        VERSION ""

        BU_: CH DIPF DIPR ETH FC HVI HVS PARTY SDCV VEH VIRT
        BO_ 962 VCLEFT_switchStatus: 8 VEH
 SG_ VCLEFT_frontBuckleSwitch m0: 48|2@1+ (1,0) [0|3] "" gtw
 SG_ VCLEFT_btnWindowSwPackUpLF m0: 32|1@1+ (1,0) [0|1] "" gtw
 SG_ VCLEFT_frontSeatTrackBack m0: 8|2@1+ (1,0) [0|3] "" gtw
 SG_ VCLEFT_btnWindowSwPackAutoDownLF m0: 35|1@1+ (1,0) [0|1] "" gtw
 SG_ VCLEFT_btnWindowSwPackDownRR m0: 46|1@1+ (1,0) [0|1] "" gtw
 SG_ VCLEFT_btnWindowSwPackAutoUpRR m0: 45|1@1+ (1,0) [0|1] "" gtw
 SG_ VCLEFT_btnWindowSwPackAutoDownRR m0: 47|1@1+ (1,0) [0|1] "" gtw
 SG_ VCLEFT_rightMirrorTilt m0: 5|3@1+ (1,0) [0|4] "" vcright
 SG_ VCLEFT_btnWindowSwPackUpRR m0: 44|1@1+ (1,0) [0|1] "" gtw
 SG_ VCLEFT_frontOccupancySwitch m0: 50|2@1+ (1,0) [0|3] "" gtw
 SG_ VCLEFT_swcRightTiltLeft m1: 8|2@1+ (1,0) [0|3] "" das
 SG_ VCLEFT_rearRightOccupancySwitch m0: 58|2@1+ (1,0) [0|3] "" gtw
 SG_ VCLEFT_btnWindowSwPackDownLF m0: 34|1@1+ (1,0) [0|1] "" gtw
 SG_ VCLEFT_btnWindowSwPackAutoUpLF m0: 33|1@1+ (1,0) [0|1] "" gtw
 SG_ VCLEFT_swcLeftTiltRight m1: 3|2@1+ (1,0) [0|3] "" das
 SG_ VCLEFT_frontSeatBackrestForward m0: 22|2@1+ (1,0) [0|3] "" gtw
 SG_ VCLEFT_swcRightTiltRight m1: 10|2@1+ (1,0) [0|3] "" das
 SG_ VCLEFT_swcLeftScrollTicks m1: 16|6@1- (1,0) [-32|31] "" das
 SG_ VCLEFT_btnWindowUpLR m1: 32|1@1+ (1,0) [0|1] "" gtw
 SG_ VCLEFT_btnWindowAutoDownLR m1: 35|1@1+ (1,0) [0|1] "" gtw
 SG_ VCLEFT_btnWindowSwPackDownRF m0: 42|1@1+ (1,0) [0|1] "" gtw
 SG_ VCLEFT_btnWindowSwPackAutoUpRF m0: 41|1@1+ (1,0) [0|1] "" gtw
 SG_ VCLEFT_frontSeatLumbarIn m0: 28|2@1+ (1,0) [0|3] "" gtw
 SG_ VCLEFT_frontSeatLiftUp m0: 18|2@1+ (1,0) [0|3] "" gtw
 SG_ VCLEFT_btnWindowSwPackDownLR m0: 38|1@1+ (1,0) [0|1] "" gtw
 SG_ VCLEFT_btnWindowSwPackAutoUpLR m0: 37|1@1+ (1,0) [0|1] "" gtw
 SG_ VCLEFT_frontSeatLumbarDown m0: 24|2@1+ (1,0) [0|3] "" gtw
 SG_ VCLEFT_driverPresent m0: 4|1@1+ (1,0) [0|1] "" das
 SG_ VCLEFT_frontSeatTiltDown m0: 12|2@1+ (1,0) [0|3] "" gtw
 SG_ VCLEFT_frontSeatTrackForward m0: 10|2@1+ (1,0) [0|3] "" gtw
 SG_ VCLEFT_rearLeftBuckleSwitch m0: 52|2@1+ (1,0) [0|3] "" gtw
 SG_ VCLEFT_hazardButtonPressed m0: 3|1@1+ (1,0) [0|1] "" gtw
 SG_ VCLEFT_swcRightScrollTicks m1: 24|6@1- (1,0) [-32|31] "" das
 SG_ VCLEFT_swcRightPressed m1: 12|2@1+ (1,0) [0|3] "" das
 SG_ VCLEFT_frontSeatLumbarOut m0: 30|2@1+ (1,0) [0|3] "" gtw
 SG_ VCLEFT_brakePressed m0: 60|1@1+ (1,0) [0|1] "" di
 SG_ VCLEFT_swcLeftTiltLeft m1: 14|2@1+ (1,0) [0|3] "" das
 SG_ VCLEFT_swcLeftPressed m1: 5|2@1+ (1,0) [0|3] "" das
 SG_ VCLEFT_btnWindowSwPackUpLR m0: 36|1@1+ (1,0) [0|1] "" gtw
 SG_ VCLEFT_frontSeatTiltUp m0: 14|2@1+ (1,0) [0|3] "" gtw
 SG_ VCLEFT_rearLeftOccupancySwitch m0: 56|2@1+ (1,0) [0|3] "" gtw
 SG_ VCLEFT_frontSeatBackrestBack m0: 20|2@1+ (1,0) [0|3] "" gtw
 SG_ VCLEFT_btnWindowSwPackAutoDownLR m0: 39|1@1+ (1,0) [0|1] "" gtw
 SG_ VCLEFT_rearCenterOccupancySwitch m0: 54|2@1+ (1,0) [0|3] "" gtw
 SG_ VCLEFT_frontSeatLumbarUp m0: 26|2@1+ (1,0) [0|3] "" gtw
 SG_ VCLEFT_frontSeatLiftDown m0: 16|2@1+ (1,0) [0|3] "" gtw
 SG_ VCLEFT_hornSwitchPressed m0: 2|1@1+ (1,0) [0|1] "" app
 SG_ VCLEFT_btnWindowSwPackUpRF m0: 40|1@1+ (1,0) [0|1] "" gtw
 SG_ VCLEFT_btnWindowAutoUpLR m1: 33|1@1+ (1,0) [0|1] "" gtw
 SG_ VCLEFT_btnWindowSwPackAutoDownRF m0: 43|1@1+ (1,0) [0|1] "" gtw
 SG_ VCLEFT_switchStatusIndex M: 0|2@1+ (1,0) [0|2] "" X
 SG_ VCLEFT_btnWindowDownLR m1: 34|1@1+ (1,0) [0|1] "" gtw
 SG_ VCLEFT_rearHVACButtonPressed m0: 61|1@1+ (1,0) [0|1] "" gtw

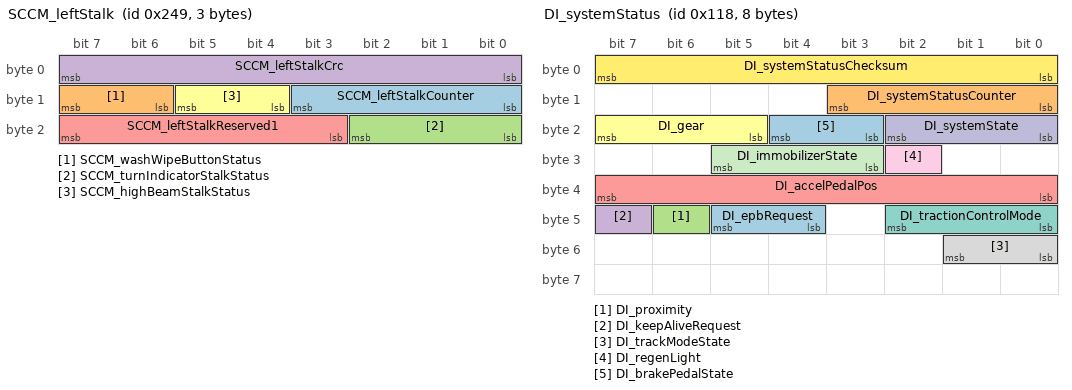
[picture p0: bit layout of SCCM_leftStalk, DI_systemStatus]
BO_ 585 SCCM_leftStalk: 3 VEH
 SG_ SCCM_leftStalkCounter : 8|4@1+ (1,0) [0|15] "" X
 SG_ SCCM_washWipeButtonStatus : 14|2@1+ (1,0) [0|3] "" das
 SG_ SCCM_turnIndicatorStalkStatus : 16|3@1+ (1,0) [0|5] "" das
 SG_ SCCM_leftStalkCrc : 0|8@1+ (1,0) [0|255] "" X
 SG_ SCCM_leftStalkReserved1 : 19|5@1+ (1,0) [0|31] "" X
 SG_ SCCM_highBeamStalkStatus : 12|2@1+ (1,0) [0|3] "" das

BO_ 280 DI_systemStatus: 8 VEH
 SG_ DI_epbRequest : 44|2@1+ (1,0) [0|2] "" epbl
 SG_ DI_systemStatusCounter : 8|4@1+ (1,0) [0|15] "" X
 SG_ DI_proximity : 46|1@1+ (1,0) [0|1] "" bms
 SG_ DI_keepAliveRequest : 47|1@1+ (1,0) [0|1] "" bms
 SG_ DI_accelPedalPos : 32|8@1+ (0.4,0) [0|100] "%" vcfront
 SG_ DI_gear : 21|3@1+ (1,0) [0|7] "" gtw
 SG_ DI_tractionControlMode : 40|3@1+ (1,0) [0|5] "" X
 SG_ DI_trackModeState : 48|2@1+ (1,0) [0|2] "" gtw
 SG_ DI_regenLight : 26|1@1+ (1,0) [0|1] "" vcleft
 SG_ DI_systemState : 16|3@1+ (1,0) [0|5] "" epbl
 SG_ DI_immobilizerState : 27|3@1+ (1,0) [0|6] "" X
 SG_ DI_systemStatusChecksum : 0|8@1+ (1,0) [0|255] "" X
 SG_ DI_brakePedalState : 19|2@1+ (1,0) [0|2] "" vcleft

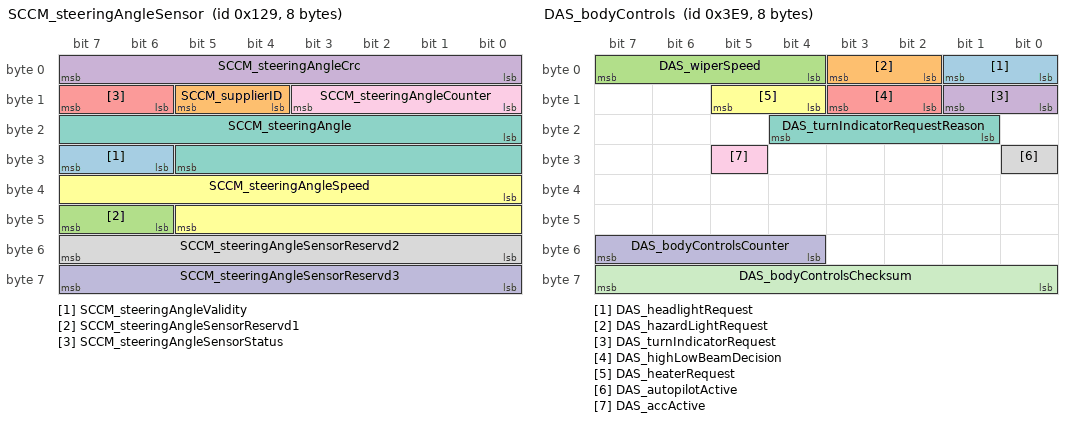
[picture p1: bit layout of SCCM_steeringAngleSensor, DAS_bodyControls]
BO_ 297 SCCM_steeringAngleSensor: 8 VEH
 SG_ SCCM_steeringAngleValidity : 30|2@1+ (1,0) [0|3] "" gtw
 SG_ SCCM_supplierID : 12|2@1+ (1,0) [0|3] "" gtw
 SG_ SCCM_steeringAngleSensorReservd1 : 46|2@1+ (1,0) [0|3] "" X
 SG_ SCCM_steeringAngleCrc : 0|8@1+ (1,0) [0|255] "" gtw
 SG_ SCCM_steeringAngleSensorStatus : 14|2@1+ (1,0) [0|3] "" aps
 SG_ SCCM_steeringAngleSpeed : 32|14@1+ (0.5,-4096) [-4096|4095.5] "deg/s" das
 SG_ SCCM_steeringAngle : 16|14@1+ (0.1,-819.2) [-819.2|819] "deg" aps
 SG_ SCCM_steeringAngleSensorReservd2 : 48|8@1+ (1,0) [0|255] "" X
 SG_ SCCM_steeringAngleCounter : 8|4@1+ (1,0) [0|15] "" gtw
 SG_ SCCM_steeringAngleSensorReservd3 : 56|8@1+ (1,0) [0|255] "" X

BO_ 1001 DAS_bodyControls: 8 VEH
 SG_ DAS_headlightRequest : 0|2@1+ (1,0) [0|3] "" aps
 SG_ DAS_hazardLightRequest : 2|2@1+ (1,0) [0|3] "" aps
 SG_ DAS_wiperSpeed : 4|4@1+ (1,0) [0|15] "" aps
 SG_ DAS_turnIndicatorRequest : 8|2@1+ (1,0) [0|3] "" aps
 SG_ DAS_highLowBeamDecision : 10|2@1+ (1,0) [0|3] "" aps
 SG_ DAS_heaterRequest : 12|2@1+ (1,0) [0|2] "" aps
 SG_ DAS_turnIndicatorRequestReason : 17|4@1+ (1,0) [0|8] "" aps
 SG_ DAS_autopilotActive : 24|1@1+ (1,0) [0|1] "" XXX
 SG_ DAS_accActive : 29|1@1+ (1,0) [0|1] "" XXX
 SG_ DAS_bodyControlsCounter : 52|4@1+ (1,0) [0|15] "" aps
 SG_ DAS_bodyControlsChecksum : 56|8@1+ (1,0) [0|255] "" aps

BO_ 1013 ID3F5VCFRONT_lighting: 8 VehicleBus
 SG_ VCFRONT_DRLLeftStatus : 36|2@1+ (1,0) [0|3] ""  Receiver
 SG_ VCFRONT_DRLRightStatus : 38|2@1+ (1,0) [0|3] ""  Receiver
 SG_ VCFRONT_ambientLightingBrightnes : 8|8@1+ (0.5,0) [0|127] "%"  Receiver
 SG_ VCFRONT_approachLightingRequest : 25|1@1+ (1,0) [0|1] ""  Receiver
 SG_ VCFRONT_courtesyLightingRequest : 24|1@1+ (1,0) [0|1] ""  Receiver
 SG_ VCFRONT_fogLeftStatus : 40|2@1+ (1,0) [0|3] ""  Receiver
 SG_ VCFRONT_fogRightStatus : 42|2@1+ (1,0) [0|3] ""  Receiver
 SG_ VCFRONT_hazardLightRequest : 4|4@1+ (1,0) [0|8] ""  Receiver
 SG_ VCFRONT_hazardSwitchBacklight : 27|1@1+ (1,0) [0|1] ""  Receiver
 SG_ VCFRONT_highBeamLeftStatus : 32|2@1+ (1,0) [0|3] ""  Receiver
 SG_ VCFRONT_highBeamRightStatus : 34|2@1+ (1,0) [0|3] ""  Receiver
 SG_ VCFRONT_highBeamSwitchActive : 58|1@1+ (1,0) [0|1] ""  Receiver
 SG_ VCFRONT_indicatorLeftRequest : 0|2@1+ (1,0) [0|2] ""  Receiver
 SG_ VCFRONT_indicatorRightRequest : 2|2@1+ (1,0) [0|2] ""  Receiver
 SG_ VCFRONT_lowBeamLeftStatus : 28|2@1+ (1,0) [0|3] ""  Receiver
 SG_ VCFRONT_lowBeamRightStatus : 30|2@1+ (1,0) [0|3] ""  Receiver
 SG_ VCFRONT_lowBeamsCalibrated : 62|1@1+ (1,0) [0|1] ""  Receiver
 SG_ VCFRONT_lowBeamsOnForDRL : 61|1@1+ (1,0) [0|1] ""  Receiver
 SG_ VCFRONT_parkLeftStatus : 54|2@1+ (1,0) [0|3] ""  Receiver
 SG_ VCFRONT_parkRightStatus : 56|2@1+ (1,0) [0|3] ""  Receiver
 SG_ VCFRONT_seeYouHomeLightingReq : 26|1@1+ (1,0) [0|1] ""  Receiver
 SG_ VCFRONT_sideMarkersStatus : 44|2@1+ (1,0) [0|3] ""  Receiver
 SG_ VCFRONT_sideRepeaterLeftStatus : 46|2@1+ (1,0) [0|3] ""  Receiver
 SG_ VCFRONT_sideRepeaterRightStatus : 48|2@1+ (1,0) [0|3] ""  Receiver
 SG_ VCFRONT_simLatchingStalk : 59|2@1+ (1,0) [0|3] ""  Receiver
 SG_ VCFRONT_switchLightingBrightness : 16|8@1+ (0.5,0) [0|127] "%"  Receiver
 SG_ VCFRONT_turnSignalLeftStatus : 50|2@1+ (1,0) [0|3] ""  Receiver
 SG_ VCFRONT_turnSignalRightStatus : 52|2@1+ (1,0) [0|3] ""  Receiver

VAL_ 1001 DAS_headlightRequest 3 "DAS_HEADLIGHT_REQUEST_INVALID" 1 "DAS_HEADLIGHT_REQUEST_ON" 0 "DAS_HEADLIGHT_REQUEST_OFF";
VAL_ 1001 DAS_hazardLightRequest 3 "DAS_REQUEST_HAZARDS_SNA" 2 "DAS_REQUEST_HAZARDS_UNUSED" 0 "DAS_REQUEST_HAZARDS_OFF" 1 "DAS_REQUEST_HAZARDS_ON";
VAL_ 1001 DAS_wiperSpeed 3 "DAS_WIPER_SPEED_3" 12 "DAS_WIPER_SPEED_12" 8 "DAS_WIPER_SPEED_8" 14 "DAS_WIPER_SPEED_14" 5 "DAS_WIPER_SPEED_5" 13 "DAS_WIPER_SPEED_13" 2 "DAS_WIPER_SPEED_2" 0 "DAS_WIPER_SPEED_OFF" 4 "DAS_WIPER_SPEED_4" 1 "DAS_WIPER_SPEED_1" 15 "DAS_WIPER_SPEED_INVALID" 10 "DAS_WIPER_SPEED_10" 11 "DAS_WIPER_SPEED_11" 7 "DAS_WIPER_SPEED_7" 9 "DAS_WIPER_SPEED_9" 6 "DAS_WIPER_SPEED_6";
VAL_ 1001 DAS_turnIndicatorRequest 0 "DAS_TURN_INDICATOR_NONE" 2 "DAS_TURN_INDICATOR_RIGHT" 3 "DAS_TURN_INDICATOR_CANCEL" 1 "DAS_TURN_INDICATOR_LEFT";
VAL_ 1001 DAS_highLowBeamDecision 2 "DAS_HIGH_BEAM_ON" 1 "DAS_HIGH_BEAM_OFF" 3 "DAS_HIGH_BEAM_SNA" 0 "DAS_HIGH_BEAM_UNDECIDED";
VAL_ 1001 DAS_heaterRequest 0 "DAS_HEATER_SNA" 2 "DAS_HEATER_ON" 1 "DAS_HEATER_OFF";
VAL_ 1001 DAS_turnIndicatorRequestReason 8 "DAS_ACTIVE_COMMANDED_LANE_CHANGE" 4 "DAS_CANCEL_LANE_CHANGE" 6 "DAS_ACTIVE_MERGE" 2 "DAS_ACTIVE_SPEED_LANE_CHANGE" 5 "DAS_CANCEL_FORK" 0 "DAS_NONE" 3 "DAS_ACTIVE_FORK" 7 "DAS_CANCEL_MERGE" 1 "DAS_ACTIVE_NAV_LANE_CHANGE";

VAL_ 1013 VCFRONT_DRLLeftStatus 2 "LIGHT_FAULT" 0 "LIGHT_OFF" 1 "LIGHT_ON" 3 "LIGHT_SNA" ;
VAL_ 1013 VCFRONT_DRLRightStatus 2 "LIGHT_FAULT" 0 "LIGHT_OFF" 1 "LIGHT_ON" 3 "LIGHT_SNA" ;
VAL_ 1013 VCFRONT_ambientLightingBrightnes 255 "SNA" ;
VAL_ 1013 VCFRONT_fogLeftStatus 2 "LIGHT_FAULT" 0 "LIGHT_OFF" 1 "LIGHT_ON" 3 "LIGHT_SNA" ;
VAL_ 1013 VCFRONT_fogRightStatus 2 "LIGHT_FAULT" 0 "LIGHT_OFF" 1 "LIGHT_ON" 3 "LIGHT_SNA" ;
VAL_ 1013 VCFRONT_hazardLightRequest 1 "HAZARD_REQUEST_BUTTON" 6 "HAZARD_REQUEST_CAR_ALARM" 5 "HAZARD_REQUEST_CRASH" 7 "HAZARD_REQUEST_DAS" 2 "HAZARD_REQUEST_LOCK" 4 "HAZARD_REQUEST_MISLOCK" 0 "HAZARD_REQUEST_NONE" 8 "HAZARD_REQUEST_UDS" 3 "HAZARD_REQUEST_UNLOCK" ;
VAL_ 1013 VCFRONT_highBeamLeftStatus 2 "LIGHT_FAULT" 0 "LIGHT_OFF" 1 "LIGHT_ON" 3 "LIGHT_SNA" ;
VAL_ 1013 VCFRONT_highBeamRightStatus 2 "LIGHT_FAULT" 0 "LIGHT_OFF" 1 "LIGHT_ON" 3 "LIGHT_SNA" ;
VAL_ 1013 VCFRONT_indicatorLeftRequest 2 "TURN_SIGNAL_ACTIVE_HIGH" 1 "TURN_SIGNAL_ACTIVE_LOW" 0 "TURN_SIGNAL_OFF" ;
VAL_ 1013 VCFRONT_indicatorRightRequest 2 "TURN_SIGNAL_ACTIVE_HIGH" 1 "TURN_SIGNAL_ACTIVE_LOW" 0 "TURN_SIGNAL_OFF" ;
VAL_ 1013 VCFRONT_lowBeamLeftStatus 2 "LIGHT_FAULT" 0 "LIGHT_OFF" 1 "LIGHT_ON" 3 "LIGHT_SNA" ;
VAL_ 1013 VCFRONT_lowBeamRightStatus 2 "LIGHT_FAULT" 0 "LIGHT_OFF" 1 "LIGHT_ON" 3 "LIGHT_SNA" ;
VAL_ 1013 VCFRONT_parkLeftStatus 2 "LIGHT_FAULT" 0 "LIGHT_OFF" 1 "LIGHT_ON" 3 "LIGHT_SNA" ;
VAL_ 1013 VCFRONT_parkRightStatus 2 "LIGHT_FAULT" 0 "LIGHT_OFF" 1 "LIGHT_ON" 3 "LIGHT_SNA" ;
VAL_ 1013 VCFRONT_sideMarkersStatus 2 "LIGHT_FAULT" 0 "LIGHT_OFF" 1 "LIGHT_ON" 3 "LIGHT_SNA" ;
VAL_ 1013 VCFRONT_sideRepeaterLeftStatus 2 "LIGHT_FAULT" 0 "LIGHT_OFF" 1 "LIGHT_ON" 3 "LIGHT_SNA" ;
VAL_ 1013 VCFRONT_sideRepeaterRightStatus 2 "LIGHT_FAULT" 0 "LIGHT_OFF" 1 "LIGHT_ON" 3 "LIGHT_SNA" ;
VAL_ 1013 VCFRONT_simLatchingStalk 0 "SIMULATED_LATCHING_STALK_IDLE" 1 "SIMULATED_LATCHING_STALK_LEFT" 2 "SIMULATED_LATCHING_STALK_RIGHT" 3 "SIMULATED_LATCHING_STALK_SNA" ;
VAL_ 1013 VCFRONT_switchLightingBrightness 255 "SNA" ;
VAL_ 1013 VCFRONT_turnSignalLeftStatus 2 "LIGHT_FAULT" 0 "LIGHT_OFF" 1 "LIGHT_ON" 3 "LIGHT_SNA" ;
VAL_ 1013 VCFRONT_turnSignalRightStatus 2 "LIGHT_FAULT" 0 "LIGHT_OFF" 1 "LIGHT_ON" 3 "LIGHT_SNA" ;
VAL_ 962 VCLEFT_frontBuckleSwitch 2 "SWITCH_ON" 0 "SWITCH_SNA" 3 "SWITCH_FAULT" 1 "SWITCH_OFF";
VAL_ 962 VCLEFT_frontSeatTrackBack 2 "SWITCH_ON" 0 "SWITCH_SNA" 3 "SWITCH_FAULT" 1 "SWITCH_OFF";
VAL_ 962 VCLEFT_rightMirrorTilt 4 "MIRROR_TILT_LEFT" 2 "MIRROR_TILT_UP" 3 "MIRROR_TILT_RIGHT" 0 "MIRROR_TILT_STOP" 1 "MIRROR_TILT_DOWN";
VAL_ 962 VCLEFT_frontOccupancySwitch 2 "SWITCH_ON" 0 "SWITCH_SNA" 3 "SWITCH_FAULT" 1 "SWITCH_OFF";
VAL_ 962 VCLEFT_swcRightTiltLeft 2 "SWITCH_ON" 0 "SWITCH_SNA" 3 "SWITCH_FAULT" 1 "SWITCH_OFF";
VAL_ 962 VCLEFT_rearRightOccupancySwitch 2 "SWITCH_ON" 0 "SWITCH_SNA" 3 "SWITCH_FAULT" 1 "SWITCH_OFF";
VAL_ 962 VCLEFT_swcLeftTiltRight 2 "SWITCH_ON" 0 "SWITCH_SNA" 3 "SWITCH_FAULT" 1 "SWITCH_OFF";
VAL_ 962 VCLEFT_frontSeatBackrestForward 2 "SWITCH_ON" 0 "SWITCH_SNA" 3 "SWITCH_FAULT" 1 "SWITCH_OFF";
VAL_ 962 VCLEFT_swcRightTiltRight 2 "SWITCH_ON" 0 "SWITCH_SNA" 3 "SWITCH_FAULT" 1 "SWITCH_OFF";
VAL_ 962 VCLEFT_frontSeatLumbarIn 2 "SWITCH_ON" 0 "SWITCH_SNA" 3 "SWITCH_FAULT" 1 "SWITCH_OFF";
VAL_ 962 VCLEFT_frontSeatLiftUp 2 "SWITCH_ON" 0 "SWITCH_SNA" 3 "SWITCH_FAULT" 1 "SWITCH_OFF";
VAL_ 962 VCLEFT_frontSeatLumbarDown 2 "SWITCH_ON" 0 "SWITCH_SNA" 3 "SWITCH_FAULT" 1 "SWITCH_OFF";
VAL_ 962 VCLEFT_frontSeatTiltDown 2 "SWITCH_ON" 0 "SWITCH_SNA" 3 "SWITCH_FAULT" 1 "SWITCH_OFF";
VAL_ 962 VCLEFT_frontSeatTrackForward 2 "SWITCH_ON" 0 "SWITCH_SNA" 3 "SWITCH_FAULT" 1 "SWITCH_OFF";
VAL_ 962 VCLEFT_rearLeftBuckleSwitch 2 "SWITCH_ON" 0 "SWITCH_SNA" 3 "SWITCH_FAULT" 1 "SWITCH_OFF";
VAL_ 962 VCLEFT_swcRightPressed 2 "SWITCH_ON" 0 "SWITCH_SNA" 3 "SWITCH_FAULT" 1 "SWITCH_OFF";
VAL_ 962 VCLEFT_frontSeatLumbarOut 2 "SWITCH_ON" 0 "SWITCH_SNA" 3 "SWITCH_FAULT" 1 "SWITCH_OFF";
VAL_ 962 VCLEFT_swcLeftTiltLeft 2 "SWITCH_ON" 0 "SWITCH_SNA" 3 "SWITCH_FAULT" 1 "SWITCH_OFF";
VAL_ 962 VCLEFT_swcLeftPressed 2 "SWITCH_ON" 0 "SWITCH_SNA" 3 "SWITCH_FAULT" 1 "SWITCH_OFF";
VAL_ 962 VCLEFT_frontSeatTiltUp 2 "SWITCH_ON" 0 "SWITCH_SNA" 3 "SWITCH_FAULT" 1 "SWITCH_OFF";
VAL_ 962 VCLEFT_rearLeftOccupancySwitch 2 "SWITCH_ON" 0 "SWITCH_SNA" 3 "SWITCH_FAULT" 1 "SWITCH_OFF";
VAL_ 962 VCLEFT_frontSeatBackrestBack 2 "SWITCH_ON" 0 "SWITCH_SNA" 3 "SWITCH_FAULT" 1 "SWITCH_OFF";
VAL_ 962 VCLEFT_rearCenterOccupancySwitch 2 "SWITCH_ON" 0 "SWITCH_SNA" 3 "SWITCH_FAULT" 1 "SWITCH_OFF";
VAL_ 962 VCLEFT_frontSeatLumbarUp 2 "SWITCH_ON" 0 "SWITCH_SNA" 3 "SWITCH_FAULT" 1 "SWITCH_OFF";
VAL_ 962 VCLEFT_frontSeatLiftDown 2 "SWITCH_ON" 0 "SWITCH_SNA" 3 "SWITCH_FAULT" 1 "SWITCH_OFF";
VAL_ 962 VCLEFT_switchStatusIndex 1 "VCLEFT_SWITCH_STATUS_INDEX_1" 2 "VCLEFT_SWITCH_STATUS_INDEX_INVALID" 0 "VCLEFT_SWITCH_STATUS_INDEX_0";
VAL_ 585 SCCM_washWipeButtonStatus 3 "SNA" 0 "NOT_PRESSED" 2 "2ND_DETENT" 1 "1ST_DETENT";
VAL_ 585 SCCM_turnIndicatorStalkStatus 3 "DOWN_1" 5 "SNA" 0 "IDLE" 1 "UP_1" 4 "DOWN_2" 2 "UP_2";
VAL_ 585 SCCM_highBeamStalkStatus 3 "SNA" 0 "IDLE" 1 "PULL" 2 "PUSH";
VAL_ 280 DI_epbRequest 0 "DI_EPBREQUEST_NO_REQUEST" 1 "DI_EPBREQUEST_PARK" 2 "DI_EPBREQUEST_UNPARK";
VAL_ 280 DI_keepAliveRequest 1 "KEEP_ALIVE" 0 "NO_REQUEST";
VAL_ 280 DI_accelPedalPos 255 "SNA";
VAL_ 280 DI_gear 1 "DI_GEAR_P" 0 "DI_GEAR_INVALID" 7 "DI_GEAR_SNA" 2 "DI_GEAR_R" 3 "DI_GEAR_N" 4 "DI_GEAR_D";
VAL_ 280 DI_tractionControlMode 0 "TC_NORMAL" 1 "TC_SLIP_START" 4 "TC_ROLLS_MODE" 2 "TC_DEV_MODE_1" 5 "TC_DYNO_MODE" 3 "TC_DEV_MODE_2";
VAL_ 280 DI_trackModeState 0 "TRACK_MODE_UNAVAILABLE" 1 "TRACK_MODE_AVAILABLE" 2 "TRACK_MODE_ON";
VAL_ 280 DI_systemState 5 "DI_SYS_ENABLE" 1 "DI_SYS_IDLE" 2 "DI_SYS_STANDBY" 0 "DI_SYS_UNAVAILABLE" 3 "DI_SYS_FAULT" 4 "DI_SYS_ABORT";
VAL_ 280 DI_immobilizerState 2 "DI_IMM_STATE_AUTHENTICATING" 0 "DI_IMM_STATE_INIT_SNA" 3 "DI_IMM_STATE_DISARMED" 4 "DI_IMM_STATE_IDLE" 6 "DI_IMM_STATE_FAULT" 1 "DI_IMM_STATE_REQUEST" 5 "DI_IMM_STATE_RESET";
VAL_ 280 DI_brakePedalState 2 "INVALID" 0 "OFF" 1 "ON";
VAL_ 297 SCCM_steeringAngleValidity 3 "SNA" 2 "INIT" 0 "INVALID" 1 "VALID";
VAL_ 297 SCCM_steeringAngleSensorStatus 0 "OK" 1 "INIT" 2 "ERROR" 3 "ERROR_INIT";
